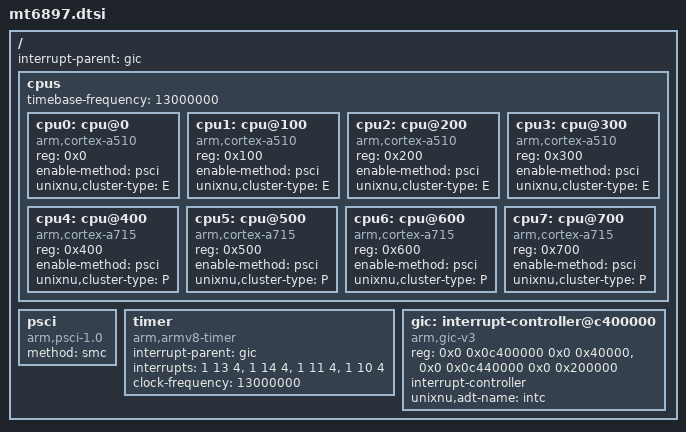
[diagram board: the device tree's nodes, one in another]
/*
 * Shared resources of the MediaTek MT6897 / MT8792 (Dimensity 8300 family).
 *
 * Values from the Lenovo TB375FC device FDT (work/evidence/20261105T073419Z/fdt.dtb) and
 * docs/hardware.md: 4x Cortex-A510 (MPIDR 0x000-0x300) + 4x Cortex-A715 (0x400-0x700),
 * GICv3 GICD 0x0c400000/0x40000 + GICR 0x0c440000/0x200000, architected timer 13 MHz,
 * PSCI over SMC. All eight cores were brought up through this PSCI on the 16.5 route.
 * Layout follows UniXNU-mt6835-common dts/mt6835.dtsi.
 */

/ {
	#address-cells = <2>;
	#size-cells = <2>;
	interrupt-parent = <&gic>;

	cpus {
		#address-cells = <1>;
		#size-cells = <0>;
		timebase-frequency = <13000000>;

		cpu0: cpu@0 {
			device_type = "cpu";
			compatible = "arm,cortex-a510";
			reg = <0x0>;
			enable-method = "psci";
			unixnu,cluster-type = "E";
		};
		cpu1: cpu@100 {
			device_type = "cpu";
			compatible = "arm,cortex-a510";
			reg = <0x100>;
			enable-method = "psci";
			unixnu,cluster-type = "E";
		};
		cpu2: cpu@200 {
			device_type = "cpu";
			compatible = "arm,cortex-a510";
			reg = <0x200>;
			enable-method = "psci";
			unixnu,cluster-type = "E";
		};
		cpu3: cpu@300 {
			device_type = "cpu";
			compatible = "arm,cortex-a510";
			reg = <0x300>;
			enable-method = "psci";
			unixnu,cluster-type = "E";
		};
		cpu4: cpu@400 {
			device_type = "cpu";
			compatible = "arm,cortex-a715";
			reg = <0x400>;
			enable-method = "psci";
			unixnu,cluster-type = "P";
		};
		cpu5: cpu@500 {
			device_type = "cpu";
			compatible = "arm,cortex-a715";
			reg = <0x500>;
			enable-method = "psci";
			unixnu,cluster-type = "P";
		};
		cpu6: cpu@600 {
			device_type = "cpu";
			compatible = "arm,cortex-a715";
			reg = <0x600>;
			enable-method = "psci";
			unixnu,cluster-type = "P";
		};
		cpu7: cpu@700 {
			device_type = "cpu";
			compatible = "arm,cortex-a715";
			reg = <0x700>;
			enable-method = "psci";
			unixnu,cluster-type = "P";
		};
	};

	psci {
		compatible = "arm,psci-1.0";
		method = "smc";
	};

	timer {
		compatible = "arm,armv8-timer";
		interrupt-parent = <&gic>;
		interrupts = <1 13 4>,	/* secure physical */
			     <1 14 4>,	/* non-secure physical */
			     <1 11 4>,	/* virtual */
			     <1 10 4>;	/* hypervisor */
		clock-frequency = <13000000>;
	};

	gic: interrupt-controller@c400000 {
		compatible = "arm,gic-v3";
		reg = <0x0 0x0c400000 0x0 0x40000>,
		      <0x0 0x0c440000 0x0 0x200000>;
		interrupt-controller;
		#interrupt-cells = <3>;
		unixnu,adt-name = "intc";
	};
};
